# DDR0_CTLPHY_WRAP_PHY_CFG register map
Vendor: Texas Instruments
Registers are 32-bit, access per field, reset 0x0 unless marked. A register's access mark holds for its fields unless they carry their own. Offsets are as the file gives them; [hi:lo] are bit positions; lines under a group give offsets from that group; {n}, {i} and the like mark numbered series; 'fields as' and 'values as' point back to an identical list.

## DDR0_CTLPHY_WRAP_PHY_CFG (part 3 of 4)
0x428 DDRPHY_BISTAR4 reset 0x3FFFF — BIST Address Register 4
  [17:0] BMROW rw — BIST Maximum Row Address: Specifies the maximum SDRAM row address to be used during BIST before the address increments to the next bank.
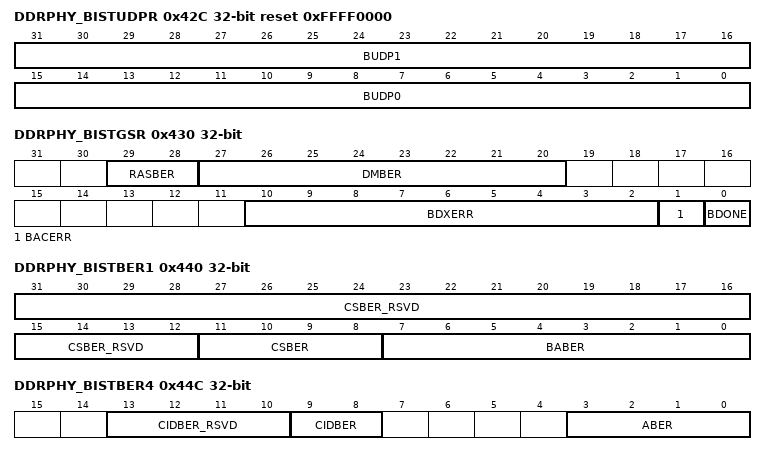
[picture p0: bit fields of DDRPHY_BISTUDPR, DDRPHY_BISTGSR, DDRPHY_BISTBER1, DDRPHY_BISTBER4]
0x42C DDRPHY_BISTUDPR rw reset 0xFFFF0000 — BIST User Data Pattern Register
  [31:16] BUDP1 — BIST User Data Pattern 1:
  [15:0] BUDP0 — BIST User Data Pattern 0:
0x430 DDRPHY_BISTGSR ro — BIST General Status Register
  [29:28] RASBER — RAS_n/ACT_n Bit Error: Indicates the number of bit errors on RAS/ACT_n
  [27:20] DMBER — DM Bit Error: Indicates the number of bit errors on data mask (DM) bit. DMBER[1:0] are for even DQS cycles first DM beat, and DMBER[3:2] are for even DQS cycles second DM beat. Similarly, DMBER[5:4] are for odd DQS cycles first DM beat, and DMBER[7:6] are for odd DQS cycles second DM beat.
  [10:2] BDXERR — BIST Data Error: indicates if set that there is a data comparison error in the byte lane. There can be single or multiple byte lanes with error, depending upon DDRPHY_BISTRR[BDXSEL] setting.
  [1] BACERR — BIST Address/Command Error: indicates if set that there is a data comparison error in the address/command lane.
  [0] BDONE — BIST Done: Indicates if set that the BIST has finished executing. This bit is reset to zero when BIST is triggered.
0x434 DDRPHY_BISTWER0 ro — BIST Word Error Register 0
  [17:0] ACWER — Address/Command Word Error: Indicates the number of word errors on the address/command lane. An error on any bit of the address/command bus increments the error count.
0x438 DDRPHY_BISTWER1 ro — BIST Word Error Register 1
  [15:0] DXWER — Byte Word Error: Indicates the number of word errors on the byte lane. An error on any bit of the data bus including the data mask bit increments the error count.
0x43C DDRPHY_BISTBER0 ro — BIST Bit Error Register 0
  [31:0] ABER — Address Bit Error: Each group of two bits indicate the bit error count on each of the up to 16 address bits. [1:0] is the error count for A[0], [3:2] for A[1], and so on.
0x440 DDRPHY_BISTBER1 ro — BIST Bit Error Register 1
  [31:12] CSBER_RSVD — Reserved.Return zeros on reads.
  [11:8] CSBER — CS_N Bit Error.
  [7:0] BABER — Bank Address Bit Error: Each group of two bits indicate the bit error count on each of the up to 4 bank address bits. [1:0] is the error count for BA[0], [3:2] for BA[1], and so on.
0x444 DDRPHY_BISTBER2 ro — BIST Bit Error Register 2
  [31:0] DQBER0 — Data Bit Error: The error count for even DQS cycles. The first 16 bits indicate the error count for the first data beat (i.e. the data driven out on DQ[7:0] on the rising edge of DQS). The second 16 bits indicate the error on the second data beat (i.e. the error count of the data driven out on DQ[7:0] on the falling edge of DQS). For each of the 16bit group, the first 2 bits are for DQ[0], the second for DQ[1], and so on.
0x448 DDRPHY_BISTBER3 ro — BIST Bit Error Register 3
  [31:0] DQBER1 — Data Bit Error: The error count for odd DQS cycles. The first 16 bits indicate the error count for the first data beat (i.e. the data driven out on DQ[7:0] on the rising edge of DQS). The second 16 bits indicate the error on the second data beat (i.e. the error count of the data driven out on DQ[7:0] on the falling edge of DQS). For each of the 16bit group, the first 2 bits are for DQ[0], the second for DQ[1], and so on.
0x44C DDRPHY_BISTBER4 ro — BIST Bit Error Register 4
  [13:10] CIDBER_RSVD — Reserved.Return zeros on reads.
  [9:8] CIDBER — Chip ID Bit Error.
  [3:0] ABER — Address Bit Error: Each group of two bits indicate the bit error count on each of the 2 most-significant address bits. [1:0] is the error count for A[16] and [3:2] for A[17].
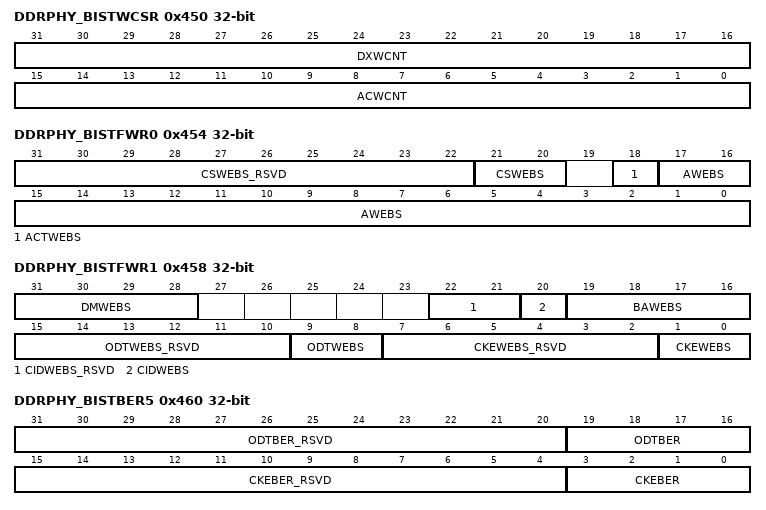
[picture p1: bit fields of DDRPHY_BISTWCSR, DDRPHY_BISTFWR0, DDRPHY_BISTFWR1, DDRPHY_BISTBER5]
0x450 DDRPHY_BISTWCSR ro — BIST Word Count Status Register
  [31:16] DXWCNT — Byte Word Count: Indicates the number of words received from the byte lane.
  [15:0] ACWCNT — Address/Command Word Count: Indicates the number of words received from the address/command lane.
0x454 DDRPHY_BISTFWR0 ro — BIST Fail Word Register 0
  [31:22] CSWEBS_RSVD — Reserved.Return zeros on reads.
  [21:20] CSWEBS — Bit status during a word error for each of the up to 12 CS# bits.
  [18] ACTWEBS — Bit status during a word error for the RAS.
  [17:0] AWEBS — Bit status during a word error for each of the up to 16 address bits.
0x458 DDRPHY_BISTFWR1 ro — BIST Fail Word Register 1
  [31:28] DMWEBS — Bit status during a word error for the data mask (DM) bit. DMWEBS [0] is for the first DM beat, DMWEBS [1] is for the second DM beat, and so on.
  [22:21] CIDWEBS_RSVD — Reserved.Return zeros on reads.
  [20] CIDWEBS — Bit status during a word error for each of the up to 3 chip ID bits.
  [19:16] BAWEBS — Bit status during a word error for each of the up to 3 bank address bits.
  [15:10] ODTWEBS_RSVD — Reserved.Return zeros on reads.
  [9:8] ODTWEBS — Bit status during a word error for each of the up to 8 ODT bits.
  [7:2] CKEWEBS_RSVD — Reserved.Return zeros on reads.
  [1:0] CKEWEBS — Bit status during a word error for each of the up to 8 CKE bits.
0x45C DDRPHY_BISTFWR2 ro — BIST Fail Word Register 2
  [31:0] DQWEBS — Bit status during a word error for each of the 8 data (DQ) bits. The first 8 bits indicate the status of the first data beat (i.e. the status of the data driven out on DQ[7:0] on the rising edge of DQS). The second 8 bits indicate the status of the second data beat (i.e. the status of the data driven out on DQ[7:0] on the falling edge of DQS), and so on. For each of the 8-bit group, the first bit is for DQ[0], the second bit is for DQ[1], and so on.
0x460 DDRPHY_BISTBER5 ro — BIST Bit Error Register 5
  [31:20] ODTBER_RSVD — Reserved.Return zeros on reads.
  [19:16] ODTBER — ODT Bit Error.
  [15:4] CKEBER_RSVD — Reserved.Return zeros on reads.
  [3:0] CKEBER — CKE Bit Error.
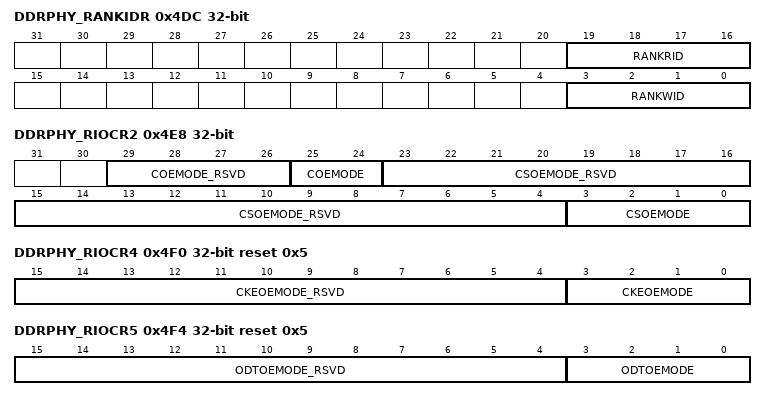
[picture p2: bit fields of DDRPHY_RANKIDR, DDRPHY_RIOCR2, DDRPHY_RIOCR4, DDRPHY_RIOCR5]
0x4DC DDRPHY_RANKIDR — Rank ID Register
  [19:16] RANKRID rw — Rank Read ID: Selects one of the up to 4 rank registers that should be read during a configuration register access. Valid values are
  [3:0] RANKWID rw — Rank Write ID: Selects one of the up to 4 rank registers that should be written during a configuration register access. Valid values are
0x4E0 DDRPHY_RIOCR0 ro — Rank I/O Configuration Register 0
0x4E4 DDRPHY_RIOCR1 ro — Rank I/O Configuration Register 1
0x4E8 DDRPHY_RIOCR2 — Rank I/O Configuration Register 2
  [29:26] COEMODE_RSVD ro — Reserved.Return zeros on reads.
  [25:24] COEMODE rw — SDRAM C Output Enable (OE) Mode Selection.
  [23:4] CSOEMODE_RSVD ro — Reserved.Return zeros on reads.
  [3:0] CSOEMODE rw — SDRAM CS_n Output Enable (OE) Mode Selection.
0x4EC DDRPHY_RIOCR3 ro — Rank I/O Configuration Register 3
0x4F0 DDRPHY_RIOCR4 reset 0x5 — Rank I/O Configuration Register 4
  [15:4] CKEOEMODE_RSVD ro — Reserved.Return zeros on reads.
  [3:0] CKEOEMODE rw — SDRAM CKE Output Enable (OE) Mode Selection.
0x4F4 DDRPHY_RIOCR5 reset 0x5 — Rank I/O Configuration Register 5
  [15:4] ODTOEMODE_RSVD ro — Reserved.Return zeros on reads.
  [3:0] ODTOEMODE rw — SDRAM On-die Termination Output Enable (OE) Mode Selection.
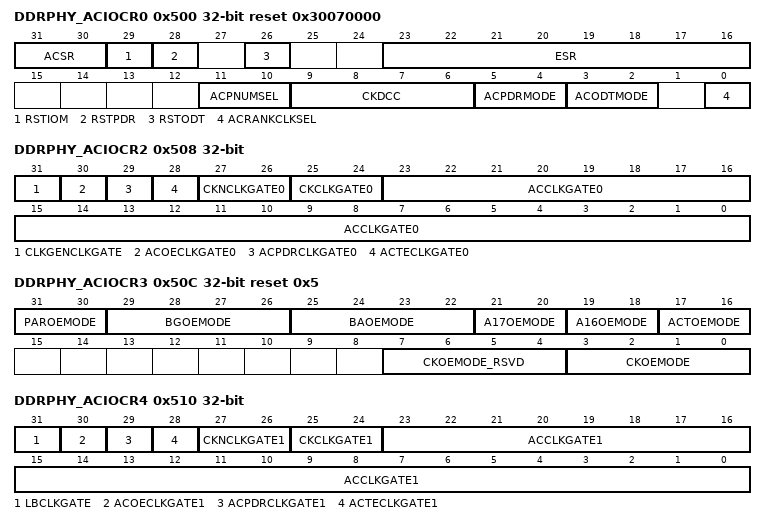
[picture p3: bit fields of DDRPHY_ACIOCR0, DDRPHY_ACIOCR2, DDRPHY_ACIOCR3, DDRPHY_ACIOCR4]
0x500 DDRPHY_ACIOCR0 reset 0x30070000 — AC I/O Configuration Register 0
  [31:30] ACSR rw — Address/Command Slew Rate: Selects slew rate of the I/O for all address and command pins.
  [29] RSTIOM rw — SDRAM Reset I/O Mode: Selects SSTL mode (when set to 0) or CMOS mode (when set to 1) of the I/O for SDRAM Reset.
  [28] RSTPDR rw — SDRAM Reset Power Down Receiver: Powers down, when set, the input receiver on the I/O for SDRAM RST# pin.
  [26] RSTODT rw — SDRAM Reset On-Die Termination: Enables, when set, the on-die termination on the I/O for SDRAM RST# pin.
  [23:16] ESR rw — Decoupling Capacitance ESR Control in D5M I/O ring.
  [11:10] ACPNUMSEL rw — Address/Command custom pin mapping configuration
  [9:6] CKDCC rw — CK Duty Cycle Correction
  [5:4] ACPDRMODE rw — AC Power Down Receiver mode for AC CK, CK_N
  [3:2] ACODTMODE rw — Address/Command On-Die mode for AC, CK, CK_N
  [0] ACRANKCLKSEL rw — Control delayed or non-delayed clock to CS_N/ODT/CKE AC slices. This bit is used in LPDDR4 CBT.
0x504 DDRPHY_ACIOCR1 rw — AC I/O Configuration Register 1
  [31:0] AOEMODE — SDRAM Address OE Mode Selection. Bits [1:0] for A[0], bits [3:2] for A[1] … bits [31:30] for A[15] Valid values are:
0x508 DDRPHY_ACIOCR2 rw — AC I/O Configuration Register 2
  [31] CLKGENCLKGATE — Clock Generator and Control Clock Gate: When set to 1, this signal will gate (stop) the clocks to all registers inside the clock generator block and the Control block.
  [30] ACOECLKGATE0 — I/O Output Enable Clock Gate for AC Macro 0:
  [29] ACPDRCLKGATE0 — I/O Power-Down Receiver Clock Gate fro AC Macro 0:
  [28] ACTECLKGATE0 — I/O Terminate Enable Clock Gate for AC Macro 0:
  [27:26] CKNCLKGATE0 — CK# Clock Gate for AC Macro 0:
  [25:24] CKCLKGATE0 — CK Clock Gate for AC Macro 0:
  [23:0] ACCLKGATE0 — Address/Command Clock Gate for AC Macro 0:
0x50C DDRPHY_ACIOCR3 reset 0x5 — AC I/O Configuration Register 3
  [31:30] PAROEMODE rw — SDRAM Parity Output Enable (OE) Mode Selection
  [29:26] BGOEMODE rw — SDRAM Bank Group Output Enable (OE) Mode Selection. Bits [1:0] for BG[0], bits [3:2] for BG[1]. Valid values are:
  [25:22] BAOEMODE rw — SDRAM Bank Address Output Enable (OE) Mode Selection. Bits [1:0] for BA[0], bits [3:2] for BA[1]. Valid values are:
  [21:20] A17OEMODE rw — SDRAM A[17] Output Enable (OE) Mode Selection. Valid values are:
  [19:18] A16OEMODE rw — SDRAM A[16] / RAS_n Output Enable (OE) Mode Selection. Valid values are:
  [17:16] ACTOEMODE rw — SDRAM ACT_n Output Enable (OE) Mode Selection (DDR4 only). Valid values are:
  [7:4] CKOEMODE_RSVD ro — Reserved.Return zeros on reads.
  [3:0] CKOEMODE rw — SDRAM CK Output Enable (OE) Mode Selection.
0x510 DDRPHY_ACIOCR4 rw — AC I/O Configuration Register 4
  [31] LBCLKGATE — Loopback Clock Gate for the AC macros: When set to 1, this signal will gate (stop) the clock to all registers inside the AC address/command loopback (LB) slices and loopback read valid slices.
  [30] ACOECLKGATE1 — I/O Output Enable Clock Gate for AC Macro 1:
  [29] ACPDRCLKGATE1 — I/O Power-Down Receiver Clock Gate for AC Macro 1:
  [28] ACTECLKGATE1 — I/O Terminate Enable Clock Gate for AC Macro 1:
  [27:26] CKNCLKGATE1 — CK# Clock Gate for AC Macro 1:
  [25:24] CKCLKGATE1 — CK Clock Gate for AC Macro 1:
  [23:0] ACCLKGATE1 — Address/Command Clock Gate for AC Macro 1:
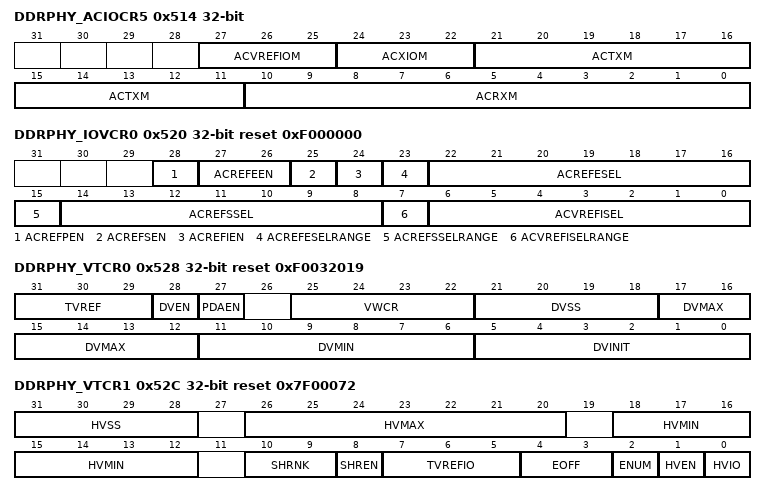
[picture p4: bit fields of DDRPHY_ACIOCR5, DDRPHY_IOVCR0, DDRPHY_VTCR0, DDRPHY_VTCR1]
0x514 DDRPHY_ACIOCR5 — AC I/O Configuration Register 5
  [27:25] ACVREFIOM rw — IOM bits for PVREF and PVREFE cells in AC IO ring
  [24:22] ACXIOM rw — I/O Mode: I/O Mode select
  [21:11] ACTXM rw — AC IO transmitter mode
  [10:0] ACRXM rw — AC IO receiver mode. Controls AC gain, DC gain, CTLE ON/OFF etc.
0x520 DDRPHY_IOVCR0 reset 0xF000000 — IO VREF Control Register 0
  [28] ACREFPEN rw — Address/command lane VREF Pad Enable: Enables the pass gate between (to connect) VREF and PAD.
  [27:26] ACREFEEN rw — Address/command lane External VREF Enable: Enables the generation of VREF value for external address/command lane differential IO buffers.
  [25] ACREFSEN rw — Address/command lane Single-End VREF Enable: Enables the generation of VREF value for internal address/command lane single-end IO buffers.
  [24] ACREFIEN rw — Address/command lane Internal VREF Enable: Enables the generation of VREF value for internal address/command lane differential IO buffers.
  [23] ACREFESELRANGE rw — External VREF generator REFSEL range select
  [22:16] ACREFESEL rw — Address/command lane External VREF Select: Selects the generated VREF value for external byte lane I/Os.
  [15] ACREFSSELRANGE rw — Single ended VREF generator REFSEL range select.
  [14:8] ACREFSSEL rw — Address/command lane Single-End VREF Select: Selects the generated VREF value for internal address/command lane single-end I/O buffers.
  [7] ACVREFISELRANGE rw — Internal VREF generator REFSEL range select
  [6:0] ACVREFISEL rw — REFSEL Control for internal AC IOs: Selects the generated VREF value for internal AC IOs.
0x528 DDRPHY_VTCR0 reset 0xF0032019 — VREF Training Control Register 0
  [31:29] TVREF rw — Number of DDRSS_PHY_CTL_CLK required to meet vref step timing (short, middle, long) requirements plus (DWC_NO_RANKS * tmod). Valid values are:
  [28] DVEN rw — DRM DQ VREF training Enable: When set, DQ VREF training will be performed for all enabled byte lanes and all enabled ranks.
  [27] PDAEN rw — Per Device Addressability Enable: When Enabled, each device will receive VREF DQ values independently.
  [25:22] VWCR rw — VREF Word Count: This register is used to program the number of words to generate during write/read for each loop in VREF training. No of words generated = (VWCR + 1) * 8
  [21:18] DVSS rw — DRAM DQ VREF step size used during DRAM VREF training. The register value of N indicates step size of (N+1). The valid step sizes are 1 to 16.
  [17:12] DVMAX rw — Maximum VREF limit value used during DRAM VREF training.
  [11:6] DVMIN rw — Minimum VREF limit value used during DRAM VREF training.
  [5:0] DVINIT rw — Initial DRAM DQ VREF value used during DRAM VREF training.
0x52C DDRPHY_VTCR1 reset 0x7F00072 — VREF Training Control Register 1
  [31:28] HVSS rw — Host VREF step size used during VREF training. The register value of N indicates step size of (N+1).The valid step sizes are 1 to 16.
  [26:20] HVMAX rw — Maximum VREF limit value used during Host VREF training.
  [18:12] HVMIN rw — Minimum VREF limit value used during Host VREF training.
  [10:9] SHRNK rw — Static Host Vref Rank Value: When SHREN is enabled, SHRNK [1:0] will be used for Vref rank control for all DQ IO buffers.
  [8] SHREN rw — Static Host Vref Rank Enable: When Enabled, vref rank control for all DQ IO buffers will be static i.e. SHRNK [1:0]. When Disabled, vref rank control for DQ IOs will be dynamically changing based on rank of read command. Single-rank systems or designs that do not include a PVREF_DAC IO cell should always use SHREN=1b1.
  [7:5] TVREFIO rw — Number of DDRSS_PHY_CTL_CLK required to meet (&gt; 200ns) VREF Settling timing requirements during Host IO VREF training. The valid values are:
  [4:3] EOFF rw — Eye LCDL Offset value for VREF training: Following are the valid values:Note:
  [2] ENUM rw — Number of LCDL Eye points for which VREF training is repeated. The valid values are:
  [1] HVEN rw — HOST (IO) internal VREF training Enable: When Set, IO VREF training will be performed for all enabled byte lanes and all enabled ranks.
  [0] HVIO rw — Host IO Type Control: Controls whether IO VREF value will be used per rank or common across all ranks.
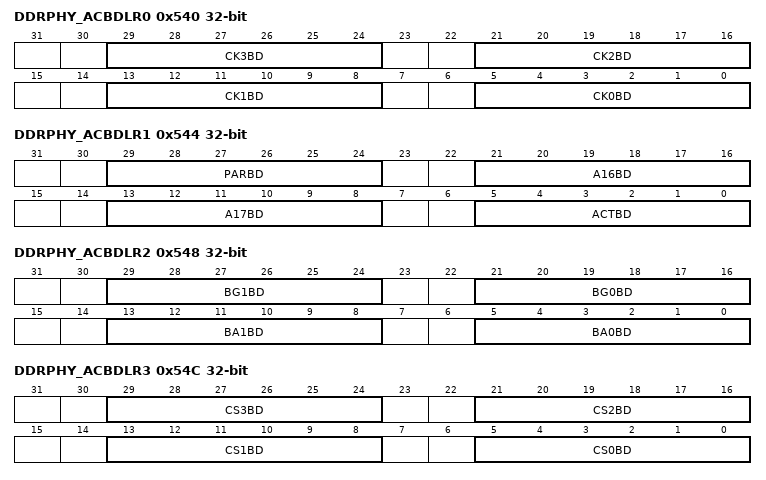
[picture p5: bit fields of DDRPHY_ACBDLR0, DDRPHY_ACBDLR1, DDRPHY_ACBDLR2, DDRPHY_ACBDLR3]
0x540 DDRPHY_ACBDLR0 — AC Bit Delay Line Register 0
  [8n+5:8n] CK{n}BD rw (n=0..3) — CK{n} Bit Delay: Delay select for the BDL on CK{n}.
0x544 DDRPHY_ACBDLR1 — AC Bit Delay Line Register 1
  [29:24] PARBD rw — Delay select for the BDL on Parity.
  [21:16] A16BD rw — Delay select for the BDL on Address A[16]. In DDR3 mode this pin is connected to WE.
  [13:8] A17BD rw — Delay select for the BDL on Address A[17]. When not in DDR4 mode, this pin is connected to CAS.
  [5:0] ACTBD rw — Delay select for the BDL on ACTN.
0x548 DDRPHY_ACBDLR2 — AC Bit Delay Line Register 2
  [29:24] BG1BD rw — Delay select for the BDL on BG[1].
  [21:16] BG0BD rw — Delay select for the BDL on BG[0].
  [13:8] BA1BD rw — Delay select for the BDL on BA[1].
  [5:0] BA0BD rw — Delay select for the BDL on BA[0].
0x54C DDRPHY_ACBDLR3 — AC Bit Delay Line Register 3
  [29:24] CS3BD ro — Delay select for the BDL on CS[3].
  [21:16] CS2BD ro — Delay select for the BDL on CS[2].
  [13:8] CS1BD rw — Delay select for the BDL on CS[1].
  [5:0] CS0BD rw — Delay select for the BDL on CS[0].
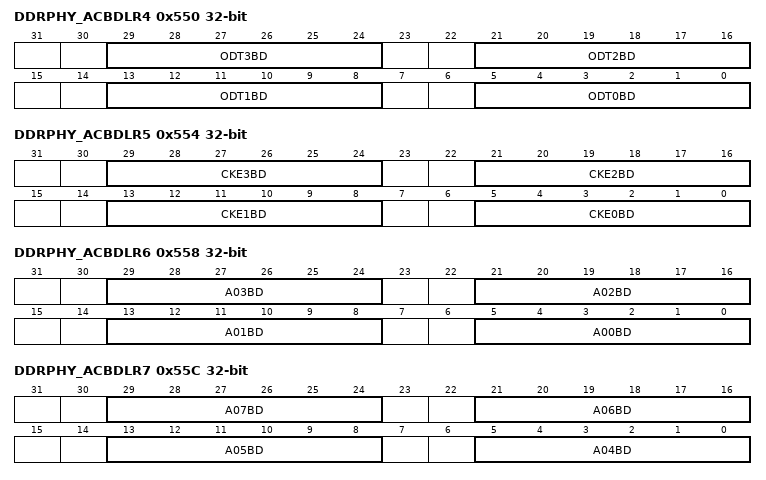
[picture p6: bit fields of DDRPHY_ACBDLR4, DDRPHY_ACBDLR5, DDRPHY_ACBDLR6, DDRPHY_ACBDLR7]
0x550 DDRPHY_ACBDLR4 — AC Bit Delay Line Register 4
  [29:24] ODT3BD ro — Delay select for the BDL on ODT[3].
  [21:16] ODT2BD ro — Delay select for the BDL on ODT[2].
  [13:8] ODT1BD rw — Delay select for the BDL on ODT[1].
  [5:0] ODT0BD rw — Delay select for the BDL on ODT[0].
0x554 DDRPHY_ACBDLR5 — AC Bit Delay Line Register 5
  [29:24] CKE3BD ro — Delay select for the BDL on CKE[3].
  [21:16] CKE2BD ro — Delay select for the BDL on CKE[2].
  [13:8] CKE1BD rw — Delay select for the BDL on CKE[1].
  [5:0] CKE0BD rw — Delay select for the BDL on CKE[0].
0x558 DDRPHY_ACBDLR6 — AC Bit Delay Line Register 6
  [8n+5:8n] A{n:02}BD rw (n=0..3) — Delay select for the BDL on Address A[{n}].
0x55C DDRPHY_ACBDLR7 — AC Bit Delay Line Register 7
  [8n-27:8n-32] A{n:02}BD rw (n=4..7) — Delay select for the BDL on Address A[{n}].
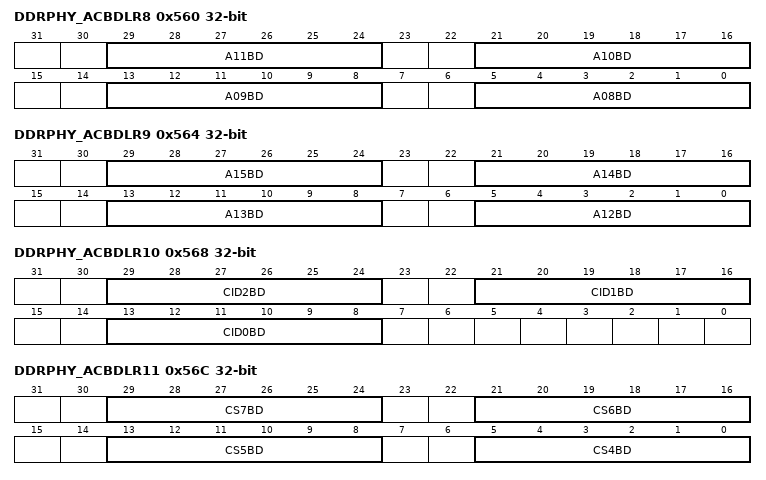
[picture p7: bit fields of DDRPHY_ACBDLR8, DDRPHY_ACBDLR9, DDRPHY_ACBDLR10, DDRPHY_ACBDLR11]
0x560 DDRPHY_ACBDLR8 — AC Bit Delay Line Register 8
  [8n-59:8n-64] A{n:02}BD rw (n=8..11) — Delay select for the BDL on Address A[{n}].
0x564 DDRPHY_ACBDLR9 — AC Bit Delay Line Register 9
  [8n-91:8n-96] A{n}BD rw (n=12..15) — Delay select for the BDL on Address A[{n}].
0x568 DDRPHY_ACBDLR10 — AC Bit Delay Line Register 10
  [29:24] CID2BD ro — Delay select for the BDL on Chip ID CID[2].
  [21:16] CID1BD ro — Delay select for the BDL on Chip ID CID[1].
  [13:8] CID0BD rw — Delay select for the BDL on Chip ID CID[0].
0x56C DDRPHY_ACBDLR11 ro — AC Bit Delay Line Register 11
  [8n-27:8n-32] CS{n}BD (n=4..7) — Delay select for the BDL on CS[{n}].
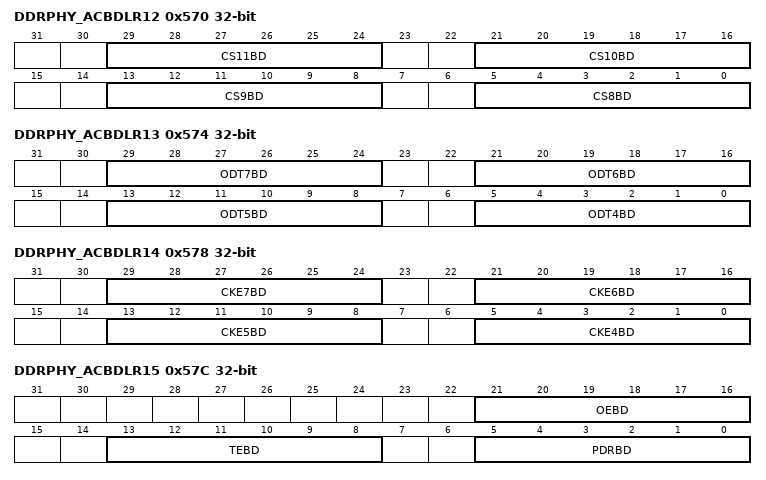
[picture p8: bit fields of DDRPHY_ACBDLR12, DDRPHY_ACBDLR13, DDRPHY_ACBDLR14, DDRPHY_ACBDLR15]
0x570 DDRPHY_ACBDLR12 ro — AC Bit Delay Line Register 12
  [8n-59:8n-64] CS{n}BD (n=8..11) — Delay select for the BDL on CS[{n}].
0x574 DDRPHY_ACBDLR13 ro — AC Bit Delay Line Register 13
  [8n-27:8n-32] ODT{n}BD (n=4..7) — Delay select for the BDL on ODT[{n}].
0x578 DDRPHY_ACBDLR14 ro — AC Bit Delay Line Register 14
  [29:24] CKE7BD — Delay select for the BDL on CKE[7].
  [21:16] CKE6BD — Delay select for the BDL on CKE[6].
  [13:8] CKE5BD — Delay select for the BDL on CKE[5]
  [5:0] CKE4BD — Delay select for the BDL on CKE[4]
0x57C DDRPHY_ACBDLR15 — AC Bit Delay Line Register 15
  [21:16] OEBD rw — OE Bit Delay: Delay select for the BDL on OE.
  [13:8] TEBD rw — TE Bit Delay: Delay select for the BDL on TE.
  [5:0] PDRBD rw — PDR Bit Delay: Delay select for the BDL on PDR.
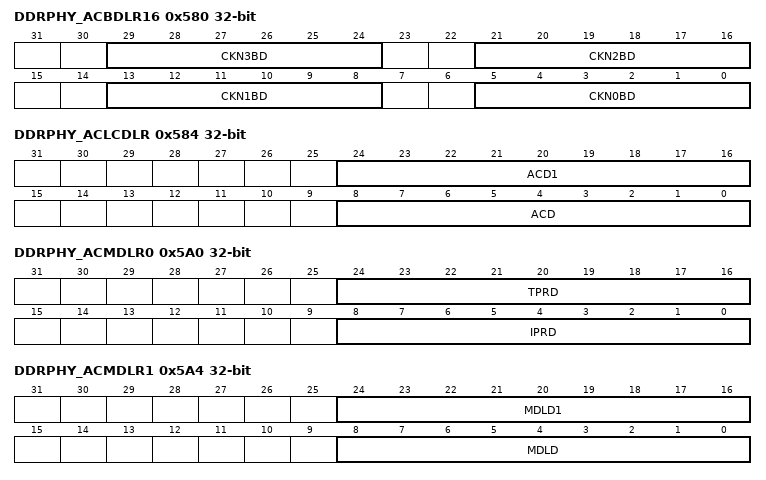
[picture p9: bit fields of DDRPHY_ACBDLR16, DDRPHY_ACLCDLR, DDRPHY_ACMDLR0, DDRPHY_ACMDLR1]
0x580 DDRPHY_ACBDLR16 — AC Bit Delay Line Register 16
  [8n+5:8n] CKN{n}BD rw (n=0..3) — CKN{n} Bit Delay: Delay select for the BDL on CKN{n}.
0x584 DDRPHY_ACLCDLR — AC Local Calibrated Delay Line Register
  [24:16] ACD1 rw — Address/Command Delay for AC Macro 1:
  [8:0] ACD rw — Address/Command Delay for AC Macro 0:
0x5A0 DDRPHY_ACMDLR0 — AC Master Delay Line Register 0
  [24:16] TPRD rw — Target Period: Target period measured by the master delay line calibration for VT drift compensation. This is the current measured value of the period and is continuously updated if the MDL is enabled to do so.
  [8:0] IPRD rw — Initial Period: Initial period measured by the master delay line calibration for VT drift compensation. This value is used as the denominator when calculating the ratios of updates during VT compensation.
0x5A4 DDRPHY_ACMDLR1 — AC Master Delay Line Register 1
  [24:16] MDLD1 rw — MDL Delay for AC Macro 1:
  [8:0] MDLD rw — MDL Delay for AC Macro 0:
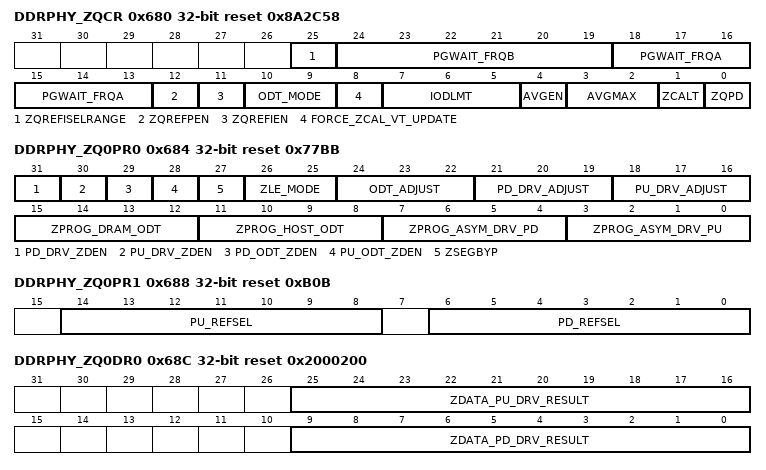
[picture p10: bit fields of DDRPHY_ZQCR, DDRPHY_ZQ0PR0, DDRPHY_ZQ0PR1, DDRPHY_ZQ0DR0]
0x680 DDRPHY_ZQCR reset 0x8A2C58 — ZQ Impedance Control Register
  [25] ZQREFISELRANGE rw — ZQ Internal VREF generator REFSEL range select: selects the ZQ internal VREF generator’s voltage range.
  [24:19] PGWAIT_FRQB rw — Programmable Wait for frequency B: specifies the number of clock cycles to remain in the WAIT state of the Impedance Controller FSM Calculated as ceiling[40 ns/Frq B period] Default: DDR3-1600
  [18:13] PGWAIT_FRQA rw — Programmable Wait for frequency A: specifies the number of clock cycles to remain in the WAIT state of the Impedance Controller FSM Calculated as ceiling[40 ns/Frq A period] Default: DDR3-1600
  [12] ZQREFPEN rw — ZQ VREF Pad Enable: Enables the pass gate between (to connect) VREF and PAD.
  [11] ZQREFIEN rw — ZQ Internal VREF Enable: Enables the generation of VREF for ZQ internal I/Os.
  [10:9] ODT_MODE rw — Choice of termination mode. This field controls how DDRPHY_ZQnPR0[ZPROG_HOST_ODT] field is used
  [8] FORCE_ZCAL_VT_UPDATE rw — When set to 1b1, forces a ZCAL VT update to the impedance calibration FSM. A write of 1b1 must be followed by a write of 1b0 to disable the request. This is a good alternative to the PHY and DFI update request signals.
  [7:5] IODLMT rw — IO VT Drift Limit: Specifies the minimum change in the Impedance calibration VT code in one direction which should result in a DFI Control/PHY update request. The limit is specified in terms of binary ZCTRL values. A value of 1b0 disables the assertion of the IO VT drift status signal.
  [4] AVGEN rw — Averaging algorithm enable, if set, enables averaging algorithm
  [3:2] AVGMAX rw — Maximum number of averaging rounds to be used by averaging algorithm. Valid values are:
  [1] ZCALT rw
  [0] ZQPD rw — ZQ Power Down; Powers down, if set, all PZQ cells
0x684 DDRPHY_ZQ0PR0 rw reset 0x77BB — ZQ n Impedance Control Program Register 0
  [31] PD_DRV_ZDEN — pull-down Drive strength ZCTRL over-ride Enable: When this bit is set, it allows users to directly drive the drive strength bits of the impedance control using the data programmed in the DDRPHY_ZQnOR[ZDATA] field. Otherwise, the ZCTRL is generated automatically by the impedance control logic. This bit takes precedence over ZSEGBYP bit.
  [30] PU_DRV_ZDEN — pull-up Drive strength ZCTRL over-ride Enable: When this bit is set, it allows users to directly drive the drive strength bits of the impedance control using the data programmed in the DDRPHY_ZQnOR[ZDATA] field. Otherwise, the ZCTRL is generated automatically by the impedance control logic. This bit takes precedence over ZSEGBYP bit. Every time this bit is set, is recommended that ZSEGBYP is also set, so that the override codes reach to I/Os immediately. Every time this bit is set, is recommended that ZSEGBYP is also set, so that the override codes reach to I/Os immediately.
  [29] PD_ODT_ZDEN — pull-down termination ZCTRL over-ride Enable: When this bit is set, it allows users to directly drive the termination bits of the impedance control using the data programmed in the DDRPHY_ZQnOR[ZDATA] field. Otherwise, the ZCTRL is generated automatically by the impedance control logic. This bit takes precedence over ZSEGBYP bit. Every time this bit is set, is recommended that ZSEGBYP is also set, so that the override codes reach to I/Os immediately.
  [28] PU_ODT_ZDEN — pull-up Termination ZCTRL over-ride Enable: When this bit is set, it allows users to directly drive the termination bits of the impedance control using the data programmed in the DDRPHY_ZQnOR[ZDATA] field. Otherwise, the ZCTRL is generated automatically by the impedance control logic. This bit takes precedence over ZSEGBYP bit. Every time this bit is set, is recommended that ZSEGBYP is also set, so that the override codes reach to I/Os immediately.
  [27] ZSEGBYP — Calibration segment bypass. When set bypass the current calibration segment during automatic calibration
  [26:25] ZLE_MODE — VREF latch mode controls the mode in which the ZLE pin of the PVREF cell is driven by the PUB. The ZLE pin is responsible for latching the ZCTRL from the PUB ZQ onto the PVREF cell.
  [24:22] ODT_ADJUST — Termination adjustment. Valid values are:
  [21:19] PD_DRV_ADJUST — pull-down drive strength adjustment. Valid values are:
  [18:16] PU_DRV_ADJUST — pull-up drive strength adjustment. Valid values are:
  [15:12] ZPROG_DRAM_ODT — Impedance Divide Ratio: Selects the external resistor divide ratio to be used for DRAM side termination calibration. This field is used only for LPDDR4 calibration to control the host side pull up drive strength. When using LPDDR4 SDRAM with VSS termination, program both the ZPROG_DRAM_ODT and ZPROG_ASYM_PU_DRV to the same value which is the desired Driver Pull-Up.
  [11:8] ZPROG_HOST_ODT — Impedance Divide Ratio: Selects the external resistor divide ratio to be used for host-side termination calibration. For DDR3 calibration, this field controls both PU and PD termination
  [7:4] ZPROG_ASYM_DRV_PD — Impedance Divide Ratio: Select the external resistor divide ratio to be used for pull-down drive calibration during asymmetric drive strength calibration. If symmetric drive strength calibration is desired, program this register field to the same value as ZPROG_ASYM_PU_DRV.
  [3:0] ZPROG_ASYM_DRV_PU — Impedance Divide Ratio: Select the external resistor divide ratio to be used for pull-up drive calibration during asymmetric drive strength calibration. If symmetric drive strength calibration is desired, program this register field to the same value as ZPROG_ASYM_PD_DRV. When using LPDDR4 SDRAM with VSS termination, the Pull-Up drive strength is determined by the value in the 'ZPROG_DRAM_ODT' field. For easier readability, program both the ZPROG_DRAM_ODT and ZPROG_ASYM_PU_DRV to the same value which is the desired Driver Pull-Up.
0x688 DDRPHY_ZQ0PR1 reset 0xB0B — ZQ n Impedance Control Program Register 1
  [14:8] PU_REFSEL rw — pull-up REFSEL for PZCTRL cell. Recommended values
  [6:0] PD_REFSEL rw — pull-down REFSEL for PZCTRL cell. Recommended values
0x68C DDRPHY_ZQ0DR0 ro reset 0x2000200 — ZQ n Impedance Control Data Register 0
  [25:16] ZDATA_PU_DRV_RESULT — pull-up drive strength calibration code result: Data value as a result of calibration or VT updates or can be used to directly drive the impedance control. The calibration result is updated either after the first calibration completes or when a VT drift related update is performed.
  [9:0] ZDATA_PD_DRV_RESULT — pull-down drive strength calibration code result: Data value as a result of calibration or VT updates or can be used to directly drive the impedance control. The calibration result is updated either after the first calibration completes or when a VT drift related update is performed.
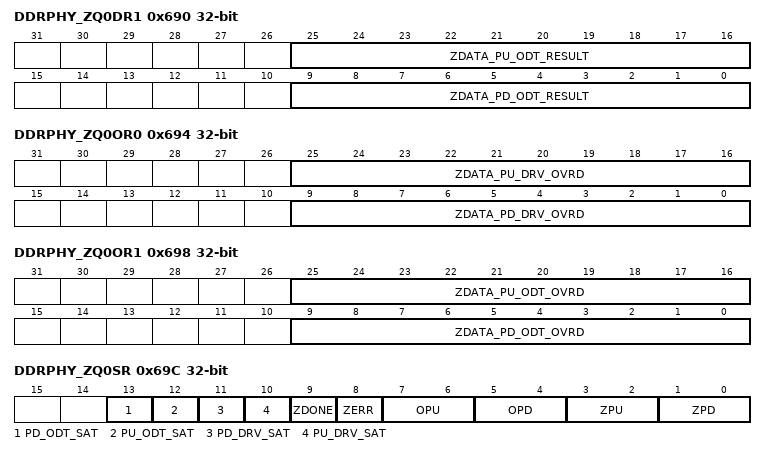
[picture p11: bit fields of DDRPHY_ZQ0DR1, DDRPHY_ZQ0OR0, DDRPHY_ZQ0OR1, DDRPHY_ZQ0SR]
0x690 DDRPHY_ZQ0DR1 ro — ZQ n Impedance Control Data Register 1
  [25:16] ZDATA_PU_ODT_RESULT — pull-up termination calibration code result: Data value as a result of calibration or VT updates or can be used to directly drive the impedance control. The calibration result is updated either after the first calibration completes or when a VT drift related update is performed.
  [9:0] ZDATA_PD_ODT_RESULT — pull-down termination calibration code result: Data value as a result of calibration or VT updates or can be used to directly drive the impedance control. The calibration result is updated either after the first calibration completes or when a VT drift related update is performed.
0x694 DDRPHY_ZQ0OR0 — ZQ n Impedance Control Override Data Register 0
  [25:16] ZDATA_PU_DRV_OVRD rw — Override value for the pull-up output impedance and is controlled by DDRPHY_ZQnPR0[DRV_PU_ZDEN]
  [9:0] ZDATA_PD_DRV_OVRD rw — Override value for the pull-down output impedance and is controlled by DDRPHY_ZQnPR0[DRV_PD_ZDEN]
0x698 DDRPHY_ZQ0OR1 — ZQ n Impedance Control Override Data Register 1
  [25:16] ZDATA_PU_ODT_OVRD rw — Override value for the pull-up termination and is controlled by DDRPHY_ZQnPR0[ODT_PU_ZDEN]
  [9:0] ZDATA_PD_ODT_OVRD rw — Override value for the pull-down termination and is controlled by DDRPHY_ZQnPR0[ODT_PD_ZDEN]
0x69C DDRPHY_ZQ0SR ro — ZQ n Impedance Control Status Register
  [13] PD_ODT_SAT — pull-down termination strength code saturated due to termination strength adjustment setting in DDRPHY_ZQnPR register. Will be zero only in DDR3 mode. If this is set to 1b1, the adjustment factor or ZPROG setting for the corresponding segment needs to be scaled.
  [12] PU_ODT_SAT — pull-up termination strength code saturated due to termination strength adjustment setting in DDRPHY_ZQnPR register. Will be zero only in DDR3 mode. If this is set to 1b1, the adjustment factor or ZPROG setting for the corresponding segment needs to be scaled.
  [11] PD_DRV_SAT — pull-down drive strength code saturated due to drive strength adjustment setting in DDRPHY_ZQnPR register. Will be non-zero only in DDR4 mode. If this is set to 1b1, the adjustment factor or ZPROG setting for the corresponding segment needs to be scaled.
  [10] PU_DRV_SAT — pull-up drive strength code saturated due to drive strength adjustment setting in DDRPHY_ZQnPR register. Will be non-zero only in DDR4 mode. If this is set to 1b1, the adjustment factor or ZPROG setting for the corresponding segment needs to be scaled.
  [9] ZDONE — Impedance Calibration Done: Indicates that the first round of impedance calibration has completed. Any time impedance calibration is restarted (after a ZCAL bypass exit or ZCAL configuration register write), this bit goes back to ‘0’ till all segments are re-calibrated, following which this bit returns to ‘1’.
  [8] ZERR — Impedance Calibration Error: If set, indicates that there was an error during impedance calibration.
  [7:6] OPU — On-die termination (ODT) pull-up calibration status. Valid status encodings are:
  [5:4] OPD — On-die termination (ODT) pull-down calibration status. Valid status encodings are:
  [3:2] ZPU — Output impedance pull-up calibration status. Valid status encodings are:
  [1:0] ZPD — Output impedance pull-down calibration status. Valid status encodings are:
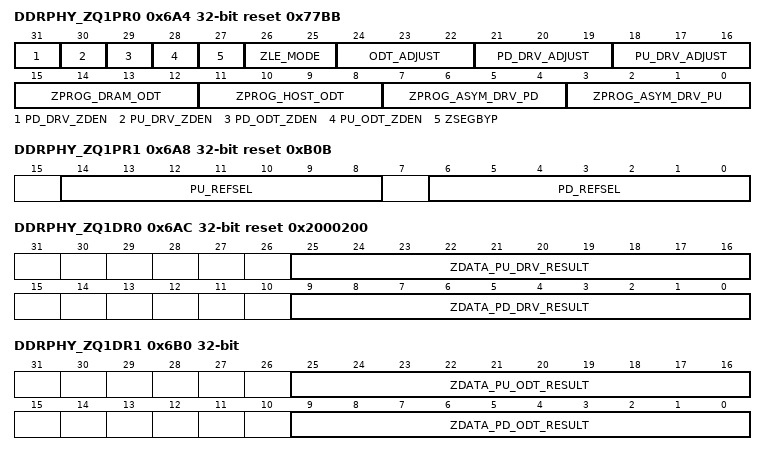
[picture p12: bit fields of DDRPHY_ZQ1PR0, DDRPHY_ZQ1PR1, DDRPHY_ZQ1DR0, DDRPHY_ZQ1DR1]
0x6A4 DDRPHY_ZQ1PR0 rw reset 0x77BB — ZQ n Impedance Control Program Register 0
  fields as DDRPHY_ZQ0PR0
0x6A8 DDRPHY_ZQ1PR1 reset 0xB0B — ZQ n Impedance Control Program Register 1
  fields as DDRPHY_ZQ0PR1
0x6AC DDRPHY_ZQ1DR0 ro reset 0x2000200 — ZQ n Impedance Control Data Register 0
  fields as DDRPHY_ZQ0DR0
0x6B0 DDRPHY_ZQ1DR1 ro — ZQ n Impedance Control Data Register 1
  fields as DDRPHY_ZQ0DR1
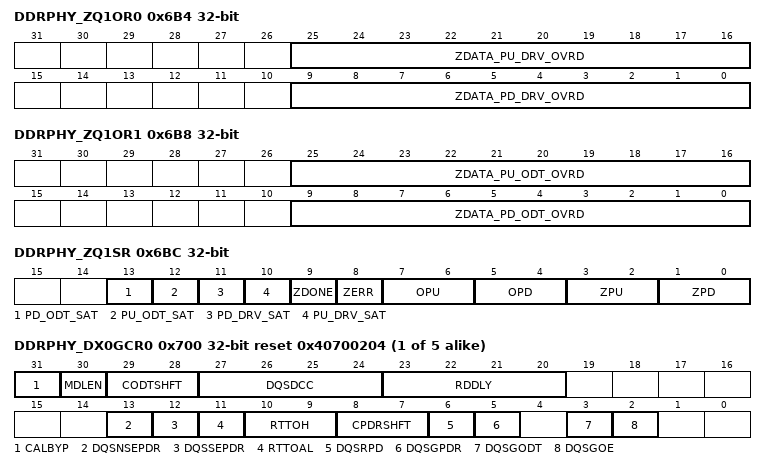
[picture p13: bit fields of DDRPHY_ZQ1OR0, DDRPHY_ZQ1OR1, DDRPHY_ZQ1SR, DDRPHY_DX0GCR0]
0x6B4 DDRPHY_ZQ1OR0 — ZQ n Impedance Control Override Data Register 0
  fields as DDRPHY_ZQ0OR0
0x6B8 DDRPHY_ZQ1OR1 — ZQ n Impedance Control Override Data Register 1
  fields as DDRPHY_ZQ0OR1
0x6BC DDRPHY_ZQ1SR ro — ZQ n Impedance Control Status Register
  fields as DDRPHY_ZQ0SR
{0x700+0x100*i} DDRPHY_DX{i}GCR0 reset 0x40700204 (i=0..4) — DATX8 n General Configuration Register 0
  [31] CALBYP rw — Calibration Bypass: Prevents, if set, period measurement calibration from automatically triggering after PHY initialization.
  [30] MDLEN rw — Master Delay Line Enable: Enables, if set, the DATX8 master delay line calibration to perform subsequent period measurements following the initial period measurements that are performed after reset or on when calibration is manually triggered. These additional measurements are accumulated and filtered as long as this bit remains high. This bit is combined with the common DATX8 MDL enable bit.
  [29:28] CODTSHFT rw — Configurable ODT(TE) phase shift applicable only when DDRPHY_DX8SLnDXCTL2[CRDEN] = 1'b1.
  [27:24] DQSDCC rw — DQS Duty Cycle Correction
  [23:20] RDDLY rw — Number of Cycles (in terms of ctl_rd_clk) to generate ctl_dx_get_static_rd input for the respective byte lane of the PHY. Valid only when RDMODE is set as static response mode.
  [13] DQSNSEPDR rw — DQSNSE Power Down Receiver: Powers down, if set, the input receiver on the I/O for DQSN gate. This bit controls the PDRSE pin on the PDQS cell.
  [12] DQSSEPDR rw — DQSSE Power Down Receiver: Powers down, if set, the input receiver on the I/O for DQS gate. This bit controls the PDRSE pin on the PDQS cell.
  [11] RTTOAL rw — RTT On Additive Latency: Indicates when the ODT control of DQ/DQS SSTL I/Os is set to the value in DQODT/DQSODT during read cycles. Valid values are:
  [10:9] RTTOH rw — RTT Output Hold: Indicates the number of clock cycles, which range from 2 - 5, after the read data postamble for which ODT control should remain set to DQSODT for DQS or DQODT for DQ/DM before disabling it (setting it to ‘0’) when using dynamic ODT control. ODT is disabled almost RTTOH clock cycles after the read postamble.
  [8:7] CPDRSHFT rw — Configurable PDR phase shift. applicable only when DDRPHY_DX8SLnDXCTL2[CRDEN] = 1'b1.
  [6] DQSRPD rw — Reserved
  [5] DQSGPDR rw — DQSG Power Down Receiver: Powers down, if set, the input receiver on the I/O for DQS gate.
  [3] DQSGODT rw — DQSG On-Die Termination: Enables, when set, the on-die termination (TE pin) on the I/O for DQS gate. Note that in typical usage, DQSGOE will always be on, rendering this control bit meaningless.
  [2] DQSGOE rw — DQSG Output Enable: Enables, when set, the output driver (OE pin) on the I/O for DQS gate.
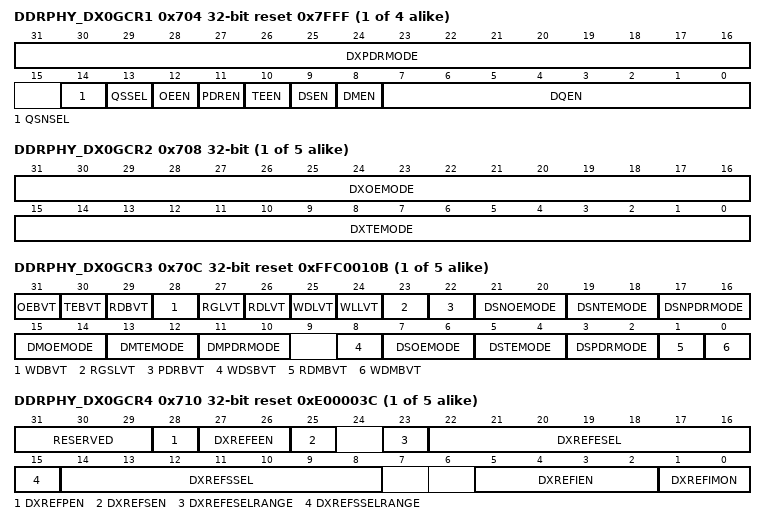
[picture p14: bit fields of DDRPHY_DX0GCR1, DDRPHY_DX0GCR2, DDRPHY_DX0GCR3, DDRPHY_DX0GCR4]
{0x704+0x100*i} DDRPHY_DX{i}GCR1 reset 0x7FFF (i=0..3) — DATX8 n General Configuration Register 1
  [31:16] DXPDRMODE rw — Enables the PDR mode values for DQ[7:0]. The bit [1:0] is for DQ[0], bit[3:2] for DQ[1] etc. Valid values are:
  [14] QSNSEL rw — Selects the delayed or non-delayed read data strobe #
  [13] QSSEL rw — Selects the delayed or non-delayed read data strobe
  [12] OEEN rw — Output Enable Clock Gate: When set to 0, this signal will gate (stop) the clocks to all registers inside the I/O output enable (D) slice
  [11] PDREN rw — I/O Power-Down Receiver Clock Gate: When set to 0, this signal will gate (stop) the clocks to all registers inside the I/O power-down receiver (D) slice.
  [10] TEEN rw — I/O Terminate Enable Clock Gate: When set to 0, this signal will gate (stop) the clocks to all registers inside the I/O terminate enable (D) slice.
  [9] DSEN rw — Data Strobe, Data Strobe # , Read Data Valid, Read Data Strobe , Read Data Strobe Gate , Control Clock Gate and Clock Generator Clock Gate: When set to 0, this signal will gate (stop) the clocks to all registers inside the corresponding block. Read Data Strobe, Read Data Strobe#, Read Data Strobe gate Enable: Enables, when set to 1
  [8] DMEN rw — Data Mask Clock Gate: When set to 0, this signal will gate (stop) the clock to all registers inside a correspondingly numbered data output (D) slice. Read Data Mask Clock Gate: When set to 0, this signal will gate (stop) the clock to all registers inside a correspondingly numbered read data input (Q) slice. Read Data Mask Enable: Enables, if set to 1, the read data path.
  [7:0] DQEN rw — Enables DQ corresponding to each bit in a byte
{0x708+0x100*i} DDRPHY_DX{i}GCR2 rw (i=0..4) — DATX8 n General Configuration Register 2
  [31:16] DXOEMODE — Enables the OE mode values for DQ[7:0]. The bit [1:0] is for DQ[0], bit[3:2] for DQ[1] etc. Valid values are:
  [15:0] DXTEMODE — Enables the TE (ODT) mode values for DQ[7:0]. The bit [1:0] is for DQ[0], bit[3:2] for DQ[1] etc. Valid values are:
{0x70C+0x100*i} DDRPHY_DX{i}GCR3 reset 0xFFC0010B (i=0..4) — DATX8 n General Configuration Register 3
  [31] OEBVT rw — Output Enable BDL VT Compensation: Enables, if set the VT drift compensation of the output enable bit delay line.
  [30] TEBVT rw — Termination Enable BDL VT Compensation: Enables, if set the VT drift compensation of the termination enable bit delay line.
  [29] RDBVT rw — Read Data BDL VT Compensation: Enables, if set the VT drift compensation of the read data bit delay lines.
  [28] WDBVT rw — Write Data BDL VT Compensation: Enables, if set the VT drift compensation of the write data bit delay lines.
  [27] RGLVT rw — Read DQS Gating LCDL Delay VT Compensation: Enables, if set the VT drift compensation of the read DQS gating LCDL.
  [26] RDLVT rw — Read DQS LCDL Delay VT Compensation: Enables, if set the VT drift compensation of the read DQS LCDL.
  [25] WDLVT rw — Write DQ LCDL Delay VT Compensation: Enables, if set the VT drift compensation of the write DQ LCDL.
  [24] WLLVT rw — Write Leveling LCDL Delay VT Compensation: Enables, if set, the VT drift compensation of the write leveling LCDL.
  [23] RGSLVT rw — Read DQS Gating Status LCDL Delay VT Compensation: Enables, if set the VT drift compensation of the read DQS gating status LCDL.
  [22] PDRBVT rw — Power Down Receiver BDL VT Compensation: Enables, if set the VT drift compensation of the power down receiver bit delay line.
  [21:20] DSNOEMODE rw — Enables the OE mode values for DQS. Valid values are:
  [19:18] DSNTEMODE rw — Enables the TE mode values for DQS. Valid values are:
  [17:16] DSNPDRMODE rw — Enables the PDR mode values for DQS. Valid values are:
  [15:14] DMOEMODE rw — Enables the OE mode values for DM. Valid values are:
  [13:12] DMTEMODE rw — Enables the TE mode values for DM. Valid values are:
  [11:10] DMPDRMODE rw — Enables the PDR mode values for DM. Valid values are:
  [8] WDSBVT rw — Write Data Strobe BDL VT Compensation: Enables, if set the VT drift compensation of the write data strobe bit delay line.
  [7:6] DSOEMODE rw — Enables the OE mode values for DQS. Valid values are:
  [5:4] DSTEMODE rw — Enables the TE mode values for DQS. Valid values are:
  [3:2] DSPDRMODE rw — Enables the PDR mode values for DQS. Valid values are:
  [1] RDMBVT rw — Read Data Mask BDL VT Compensation: Enables, if set the VT drift compensation of the read data mask bit delay lines.
  [0] WDMBVT rw — Write Data Mask BDL VT Compensation: Enables, if set the VT drift compensation of the write data mask bit delay lines.
{0x710+0x100*i} DDRPHY_DX{i}GCR4 reset 0xE00003C (i=0..4) — DATX8 n General Configuration Register 4
  [31:29] RESERVED ro — Byte lane VREF IOM (Used only by D4MU IOs)
  [28] DXREFPEN rw — Byte Lane VREF Pad Enable: Enables the pass gate between (to connect) VREF and PAD.
  [27:26] DXREFEEN rw — Byte Lane External VREF Enable: Enables the generation of VREF value for external byte lane differential IO buffers.
  [25] DXREFSEN rw — Byte Lane Single-End VREF Enable: Enables the generation of VREF value for internal byte lane single-end IO buffers. This is for DQSG loopback read gating path which is single ended. The Vref value is defined in DDRPHY_DXnGCR4[DXREFSSEL].
  [23] DXREFESELRANGE rw — External VREF generator REFSEL range select
  [22:16] DXREFESEL rw — Byte Lane External VREF Select: Selects the generated VREF value for external byte lane I/Os.
  [15] DXREFSSELRANGE rw — Selects generated MVREFSE range used for PDQS IO (read DQS gate)
  [14:8] DXREFSSEL rw — Selects reference value for single ended comparator in PDQS IO (read DQS gate).
  [5:2] DXREFIEN rw — VREF Enable control for DQ IO (Single Ended) buffers of a byte lane. This applies to DQ and DM I/Os
  [1:0] DXREFIMON rw — VRMON control for DQ IO (Single Ended) buffers of a byte lane.
{0x714+0x100*i} DDRPHY_DX{i}GCR5 reset 0x9090909 (i=0..4) — DATX8 n General Configuration Register 5
  [8n+6:8n] DXREFISELR{n} rw (n=0..3) — Rank{n}: Select value of internally generated Vref for PDDRIO
{0x718+0x100*i} DDRPHY_DX{i}GCR6 reset 0x9090909 (i=0..4) — DATX8 n General Configuration Register 6
  [29:24] DXDQVREFR3 rw — DRAM DQ VREF Select for Rank3: Selects the generated VREF value for external DRAM device..
  [21:16] DXDQVREFR2 rw — DRAM DQ VREF Select for Rank2: Selects the generated VREF value for external DRAM device.
  [13:8] DXDQVREFR1 rw — DRAM DQ VREF Select for Rank1: Selects the generated VREF value for external DRAM device.
  [5:0] DXDQVREFR0 rw — DRAM DQ VREF Select for Rank0: Selects the generated VREF value for external DRAM device.
{0x71C+0x100*i} DDRPHY_DX{i}GCR7 reset 0x100 (i=0..4) — DATX8 n General Configuration Register 7
  [9] DCALTYPE rw — DDL Calibration Type: Select the algorithm in DDL Calibration. Select the algorithm as follows:
  [8:0] DCALSVAL rw — DDL Calibration Starting Value: Initial LCDL delay select value in DDL Calibration.
{0x728+0x100*i} DDRPHY_DX{i}DQMAP0 reset 0x80043210 (i=0..4) — DATX8 n DQ/DM Mapping Register 0
  [31] MAPOK ro — Checksum bit. MAPOK is set to '1' if and only if all DQxMAP fields in DDRPHY_DXnDQMAP0 and DDRPHY_DXnDQMAP1 are uniquely set to values in the correct range (0 to 8).
  [4n+3:4n] DQ{n}MAP rw (n=1..4) — DQ bit {n} DATX8 slice mapping index. Value range of 0 to 8. See DQ0MAP description
  [3:0] DQ0MAP rw — DQ bit 0 DATX8 slice mapping index. Value range of 0 to 8. The programmed value defines the DATX8 DQ/DM slice order that the byte lane DQ[0] bit is mapped to; for example, setting DQ0MAP to 0x5 will configure DQ[0] for this byte lane to be routed to the 6th DATX8 DQ slice counted from the bottom (or from the left in vertical slice implementations).
{0x72C+0x100*i} DDRPHY_DX{i}DQMAP1 reset 0x80008765 (i=0..4) — DATX8 n DQ/DM Mapping Register 1
  [31] MAPOK ro — Checksum bit. MAPOK is set to '1' if and only if all DQxMAP fields in DDRPHY_DXnDQMAP0 and DDRPHY_DXnDQMAP1 are uniquely set to values in the correct range (0 to 9).
  [15:12] DMMAP rw — DM bit DATX8 slice mapping index. Value range of 0 to 8. See DQ5MAP description
  [11:8] DQ7MAP rw — DQ bit 7 DATX8 slice mapping index. Value range of 0 to 8. See DQ5MAP description
  [7:4] DQ6MAP rw — DQ bit 6 DATX8 slice mapping index. Value range of 0 to 8. See DQ5MAP description
  [3:0] DQ5MAP rw — DQ bit 5 DATX8 slice mapping index. Value range of 0 to 8. The programmed value defines the DATX8 DQ/DM slice order that the byte lane DQ[5] bit is mapped to; for example, setting DQ6MAP to 0x2 will configure DQ[5] for this byte lane to be routed to the 2nd DATX8 DQ slice counted from the bottom (or from the left in vertical slice implementations).
{0x740+0x100*i} DDRPHY_DX{i}BDLR0 (i=0..4) — DATX8 n Bit Delay Line Register 0
  [29:24] DQ3WBD rw — DQ3 Write Bit Delay: Delay select for the BDL on DQ3 write path
  [21:16] DQ2WBD rw — DQ2 Write Bit Delay: Delay select for the BDL on DQ2 write path.
  [13:8] DQ1WBD rw — DQ1 Write Bit Delay: Delay select for the BDL on DQ1 write path.
  [5:0] DQ0WBD rw — DQ0 Write Bit Delay: Delay select for the BDL on DQ0 write path.
